# ECD3_IPGW_ICONT register map
Vendor: Texas Instruments
Peripheral module from a debugger description file (folder TDA2Px).
Registers are 32-bit, access not given, reset 0x0 unless marked. A register's access mark holds for its fields unless they carry their own. Offsets are as the file gives them; lines under a group give offsets from that group; [hi:lo] are bit positions; {n}, {i} and the like mark numbered series; 'fields as' and 'values as' point back to an identical list; <NAME> marks a mode.

## ECD3_IPGW_ICONT
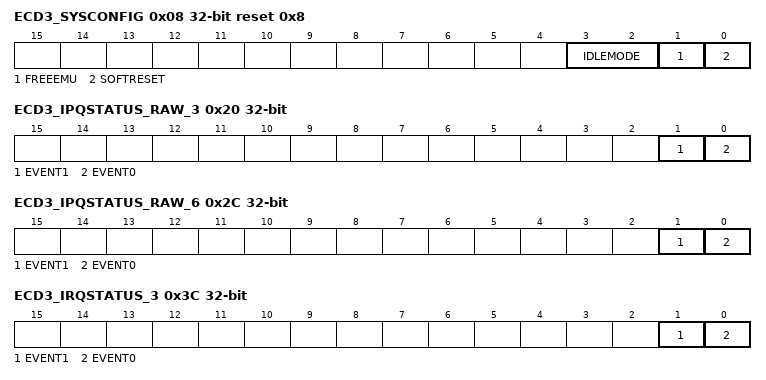
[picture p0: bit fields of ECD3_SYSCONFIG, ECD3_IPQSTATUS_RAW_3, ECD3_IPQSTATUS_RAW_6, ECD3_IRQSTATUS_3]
0x08 ECD3_SYSCONFIG access per field reset 0x8 — Clock management configuration
  [3:2] IDLEMODE rw — Configuration of the local target state management mode. By definition, target can handle read/write transaction as long as it is out of IDLE state. 0x0: Force-idle mode: local target's idle state follows (acknowledges) the system's idle requests unconditionally, that is, regardless of the IP module's internal requirements. Backup mode, for debug only. 0x1: No-idle mode: local target never enters idle state. Backup mode, for debug only. 0x2: Smart-idle mode: local target's idle state eventually follows (acknowledges) the system's idle requests, depending on the IP module's internal requirements. IP module shall not generate (IRQ- or DMA-request-related) wake-up events. wake-up 0x3: Smart-idle wake-up-capable mode: local target's idle state eventually follows (acknowledges) the system's idle requests, depending on the IP module's internal requirements. IP module may generate (IRQ- or DMA-request-related) wake-up events when in idle state. Mode is only relevant if the appropriate IP module 'swake-up' output(s) is (are) implemented.
  [1] FREEEMU rw — Sensitivity to emulation (debug) suspend input signal. 0x0: IP module is sensitive to emulation suspend 0x1: IP module is not sensitive to emulation suspend
  [0] SOFTRESET rw — Software reset Read 0x0: Reset done, no pending action Read 0x1: Reset (software or other) on going Write 0x0: No action Write 0x1: Initiate software reset
0x0C ECD3_IRQ_EOI access per field — End Of Interrupt number specification
  [2:0] LINE_NUMBER rw — Software End Of Interrupt (EOI) control. Write number of interrupt output. Write 0x0: EOI for interrupt output line #0 Write 0x1: EOI for interrupt output line #1 Write 0x2: EOI for interrupt output line #2 Write 0x3: EOI for interrupt output line #3 Write 0x4: EOI for interrupt output line #4 Write 0x5: EOI for interrupt output line #5 Write 0x6: EOI for interrupt output line #6 Read 0x0: Reads always 0 (no EOI memory)
{0x14+4i} ECD3_IPQSTATUS_RAW_{i} (i=0..2) — Per-event raw interrupt status vector, line #{i}. Raw status is set even if event is not enabled. Write 1 to set the (raw) status, mostly for debug.
  [0] EVENT0 — settable raw status for event #0 Write 0x0: No action Read 0x0: No event pending Read 0x1: Event pending Write 0x1: Set event (debug) (access RW W1toSet)
0x20 ECD3_IPQSTATUS_RAW_3 — Per-event raw interrupt status vector, line #3. Raw status is set even if event is not enabled. Write 1 to set the (raw) status, mostly for debug.
  [1] EVENT1 — settable raw status for event #1 Write 0x0: No action Read 0x0: No event pending Read 0x1: Event pending Write 0x1: Set event (debug) (access RW W1toSet)
  [0] EVENT0 — settable raw status for event #0 Write 0x0: No action Read 0x0: No event pending Read 0x1: Event pending Write 0x1: Set event (debug) (access RW W1toSet)
0x24 ECD3_IPQSTATUS_RAW_4 — Per-event raw interrupt status vector, line #0. Raw status is set even if event is not enabled. Write 1 to set the (raw) status, mostly for debug.
  fields as ECD3_IPQSTATUS_RAW_0
0x28 ECD3_IPQSTATUS_RAW_5 — Per-event raw interrupt status vector, line #0. Raw status is set even if event is not enabled. Write 1 to set the (raw) status, mostly for debug.
  fields as ECD3_IPQSTATUS_RAW_0
0x2C ECD3_IPQSTATUS_RAW_6 — Per-event raw interrupt status vector, line #0. Raw status is set even if event is not enabled. Write 1 to set the (raw) status, mostly for debug.
  fields as ECD3_IPQSTATUS_RAW_3
{0x30+4i} ECD3_IRQSTATUS_{i} (i=0..2) — Per-event 'enabled' interrupt status vector, line #{i}. Enabled status is not set unless event is enabled. Write 1 to clear the status after interrupt has been serviced (raw status gets cleared, that is, even if not enabled).
  [0] EVENT0 — clearable, enabled status for event #0 Write 0x0: No action Read 0x0: No (enabled) event pending Read 0x1: Event pending Write 0x1: Clear (raw) event (access RW W1toClr)
0x3C ECD3_IRQSTATUS_3 — Per-event 'enabled' interrupt status vector, line #3. Enabled status is not set unless event is enabled. Write 1 to clear the status after interrupt has been serviced (raw status gets cleared, that is, even if not enabled).
  [1] EVENT1 — clearable, enabled status for event #1 Write 0x0: No action Read 0x0: No (enabled) event pending Read 0x1: Event pending Write 0x1: Clear (raw) event (access RW W1toClr)
  [0] EVENT0 — clearable, enabled status for event #0 Write 0x0: No action Read 0x0: No (enabled) event pending Read 0x1: Event pending Write 0x1: Clear (raw) event (access RW W1toClr)
0x40 ECD3_IRQSTATUS_4 — Per-event 'enabled' interrupt status vector, line #0. Enabled status is not set unless event is enabled. Write 1 to clear the status after interrupt has been serviced (raw status gets cleared, that is, even if not enabled).
  fields as ECD3_IRQSTATUS_0
0x44 ECD3_IRQSTATUS_5 — Per-event 'enabled' interrupt status vector, line #0. Enabled status is not set unless event is enabled. Write 1 to clear the status after interrupt has been serviced (raw status gets cleared, that is, even if not enabled).
  fields as ECD3_IRQSTATUS_0
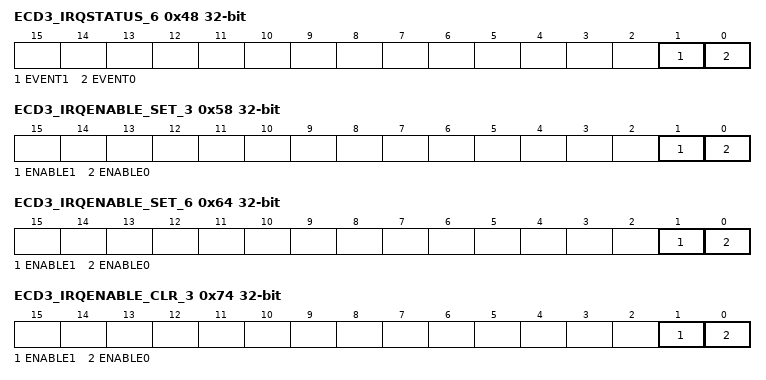
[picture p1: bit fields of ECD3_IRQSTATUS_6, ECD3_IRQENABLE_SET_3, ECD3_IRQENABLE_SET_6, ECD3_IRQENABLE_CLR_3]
0x48 ECD3_IRQSTATUS_6 — Per-event 'enabled' interrupt status vector, line #3. Enabled status is not set unless event is enabled. Write 1 to clear the status after interrupt has been serviced (raw status gets cleared, that is, even if not enabled).
  fields as ECD3_IRQSTATUS_3
{0x4C+4i} ECD3_IRQENABLE_SET_{i} (i=0..2) — Per-event interrupt enable bit vector, line #{i}. Write 1 to set (enable interrupt). Readout equal to corresponding _CLR register.
  [0] ENABLE0 — Enable for event #0. Write 0x0: No action Write 0x1: Enable interrupt Read 0x0: Interrupt disabled (masked) Read 0x1: Interrupt enabled (access RW W1toSet)
0x58 ECD3_IRQENABLE_SET_3 — Per-event interrupt enable bit vector, line #0. Write 1 to set (enable interrupt). Readout equal to corresponding _CLR register.
  [1] ENABLE1 — Enable for event #1. Write 0x0: No action Write 0x1: Enable interrupt Read 0x0: Interrupt disabled (masked) Read 0x1: Interrupt enabled (access RW W1toSet)
  [0] ENABLE0 — Enable for event #0. Write 0x0: No action Write 0x1: Enable interrupt Read 0x0: Interrupt disabled (masked) Read 0x1: Interrupt enabled (access RW W1toSet)
0x5C ECD3_IRQENABLE_SET_4 — Per-event interrupt enable bit vector, line #0. Write 1 to set (enable interrupt). Readout equal to corresponding _CLR register.
  fields as ECD3_IRQENABLE_SET_0
0x60 ECD3_IRQENABLE_SET_5 — Per-event interrupt enable bit vector, line #0. Write 1 to set (enable interrupt). Readout equal to corresponding _CLR register.
  fields as ECD3_IRQENABLE_SET_0
0x64 ECD3_IRQENABLE_SET_6 — Per-event interrupt enable bit vector, line #0. Write 1 to set (enable interrupt). Readout equal to corresponding _CLR register.
  fields as ECD3_IRQENABLE_SET_3
{0x68+4i} ECD3_IRQENABLE_CLR_{i} (i=0..2) — Per-event interrupt enable bit vector, line #{i}. Write 1 to clear (disable interrupt). Readout equal to corresponding _SET register.
  [0] ENABLE0 — Enable for event #0. Write 0x0: No action Write 0x1: Disable interrupt Read 0x0: Interrupt disabled (masked) Read 0x1: Interrupt enabled (access RW W1toClr)
0x74 ECD3_IRQENABLE_CLR_3 — Per-event interrupt enable bit vector, line #2. Write 1 to clear (disable interrupt). Readout equal to corresponding _SET register.
  [1] ENABLE1 — Enable for event #1. Write 0x0: No action Write 0x1: Disable interrupt Read 0x0: Interrupt disabled (masked) Read 0x1: Interrupt enabled (access RW W1toClr)
  [0] ENABLE0 — Enable for event #0. Write 0x0: No action Write 0x1: Disable interrupt Read 0x0: Interrupt disabled (masked) Read 0x1: Interrupt enabled (access RW W1toClr)
0x78 ECD3_IRQENABLE_CLR_4 — Per-event interrupt enable bit vector, line #0. Write 1 to clear (disable interrupt). Readout equal to corresponding _SET register.
  fields as ECD3_IRQENABLE_CLR_0
0x7C ECD3_IRQENABLE_CLR_5 — Per-event interrupt enable bit vector, line #0. Write 1 to clear (disable interrupt). Readout equal to corresponding _SET register.
  fields as ECD3_IRQENABLE_CLR_0
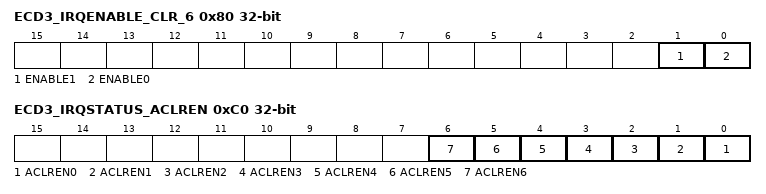
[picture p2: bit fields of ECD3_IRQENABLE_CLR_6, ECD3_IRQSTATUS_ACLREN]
0x80 ECD3_IRQENABLE_CLR_6 — Per-event interrupt enable bit vector, line #2. Write 1 to clear (disable interrupt). Readout equal to corresponding _SET register.
  fields as ECD3_IRQENABLE_CLR_3
0xC0 ECD3_IRQSTATUS_ACLREN access per field — Auto Clear enable
  [n] ACLREN{n} rw (n=0..6) — For line {n}
